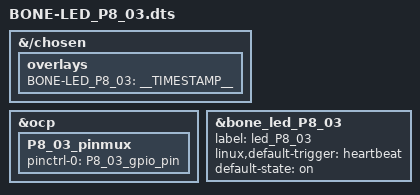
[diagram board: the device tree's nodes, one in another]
/*
 * Copyright (C) 2020 - 2022 Deepak Khatri <lorforlinux@beagleboard.org>
 *
 * See Cape Interface Spec page for more info on Bone Buses
 * https://docs.beagleboard.org/0.0/boards/capes/cape-interface-spec.html#beaglebone-cape-interface-spec
 *
 * Virtual cape for LED on P8_03 
 * Supports BBB, BBBWL, BBAI, and BBAI-64
 *
 * This program is free software; you can redistribute it and/or modify
 * it under the terms of the GNU General Public License version 2 as
 * published by the Free Software Foundation.
 */
 
/dts-v1/;
/plugin/;
 
&{/chosen} {
	overlays {
		BONE-LED_P8_03 = __TIMESTAMP__;
	};
};
 
/*
 * Update the default pinmux of the pins.
 * See these files for the phandles (&P9_* & &P8_*)
 * BeagleBoard-DeviceTrees/v5.10.x-ti-unified/src/arm/am335x-bone-common-univ.dtsi
 * BeagleBoard-DeviceTrees/v5.10.x-ti-unified/src/arm/am572x-bone-common-univ.dtsi
 * BeagleBoard-DeviceTrees/v5.10.x-ti-unified/src/arm64/k3-j721e-beagleboneai64-bone-buses.dtsi
 */
&ocp {
	P8_03_pinmux { pinctrl-0 = <&P8_03_gpio_pin>;};	
};

/*
 * Easy LED control through sysfs (/sys/class/leds/) using gpio-leds driver
 * See these files for the bone_led_P8_#/bone_led_P9_#  definition
 * https://git.beagleboard.org/beagleboard/BeagleBoard-DeviceTrees/-/blob/v5.10.x-ti-unified/src/arm/bbai-bone-buses.dtsi
 * https://git.beagleboard.org/beagleboard/BeagleBoard-DeviceTrees/-/blob/v5.10.x-ti-unified/src/arm/bbb-bone-buses.dtsi
 * https://git.beagleboard.org/beagleboard/BeagleBoard-DeviceTrees/-/blob/v5.10.x-ti-unified/src/arm64/k3-j721e-beagleboneai64-bone-buses.dtsi
 * 
 */

&bone_led_P8_03 {
    status = "okay";
    // access: sys/class/leds/led_P8_03
    label = "led_P8_03";
    linux,default-trigger = "heartbeat";
    default-state = "on";
};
